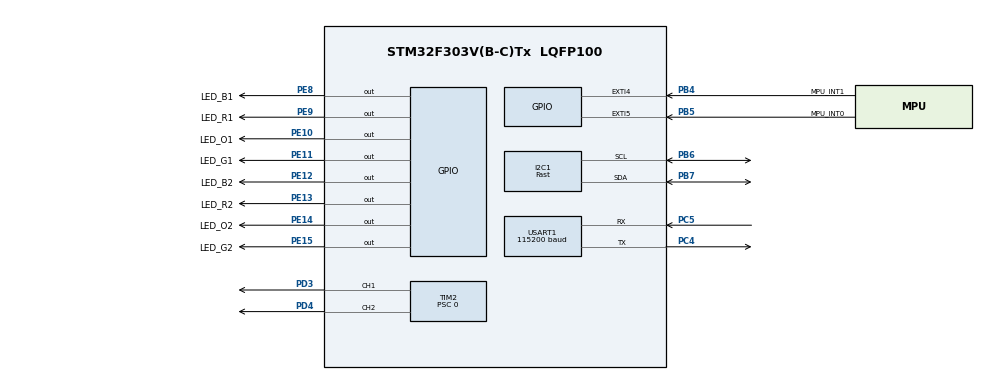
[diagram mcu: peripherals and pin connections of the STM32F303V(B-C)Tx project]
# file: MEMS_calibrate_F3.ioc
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Dma.Request0=USART1_TX
Dma.USART1_TX.0.Direction=DMA_MEMORY_TO_PERIPH
Dma.USART1_TX.0.Instance=DMA1_Channel4
Dma.USART1_TX.0.MemDataAlignment=DMA_MDATAALIGN_BYTE
Dma.USART1_TX.0.MemInc=DMA_MINC_ENABLE
Dma.USART1_TX.0.Mode=DMA_NORMAL
Dma.USART1_TX.0.PeriphDataAlignment=DMA_PDATAALIGN_BYTE
Dma.USART1_TX.0.PeriphInc=DMA_PINC_DISABLE
Dma.USART1_TX.0.Priority=DMA_PRIORITY_LOW
I2C1.I2C_Speed_Mode=I2C_Fast
I2C1.Timing=0x0000020B
Mcu.Family=STM32F3
Mcu.Name=STM32F303V(B-C)Tx
Mcu.Package=LQFP100
NVIC.DMA1_Channel4_IRQn=true\:0\:0\:false\:false\:true\:false\:true
NVIC.EXTI4_IRQn=true\:0\:0\:false\:false\:true\:true\:true
NVIC.EXTI9_5_IRQn=true\:0\:0\:false\:false\:true\:true\:true
NVIC.PriorityGroup=NVIC_PRIORITYGROUP_4
NVIC.USART1_IRQn=true\:0\:0\:false\:false\:true\:true\:true
PA13.Mode=Trace_Asynchronous_SW
PA13.Signal=SYS_JTMS-SWDIO
PA14.Mode=Trace_Asynchronous_SW
PA14.Signal=SYS_JTCK-SWCLK
PB3.Mode=Trace_Asynchronous_SW
PB3.Signal=SYS_JTDO-TRACESWO
PB4.GPIO_Label=MPU_INT1
PB4.GPIO_PuPd=GPIO_NOPULL
PB4.Signal=GPXTI4
PB5.GPIO_Label=MPU_INT0
PB5.GPIO_PuPd=GPIO_NOPULL
PB5.Signal=GPXTI5
PB6.Mode=I2C
PB6.Signal=I2C1_SCL
PB7.Mode=I2C
PB7.Signal=I2C1_SDA
PC4.Mode=Asynchronous
PC4.Signal=USART1_TX
PC5.Mode=Asynchronous
PC5.Signal=USART1_RX
PD3.GPIO_Speed=GPIO_SPEED_FREQ_HIGH
PD3.Signal=S_TIM2_CH1_ETR
PD4.GPIO_Speed=GPIO_SPEED_FREQ_HIGH
PD4.Signal=S_TIM2_CH2
PE10.GPIO_Label=LED_O1
PE10.Signal=GPIO_Output
PE11.GPIO_Label=LED_G1
PE11.Signal=GPIO_Output
PE12.GPIO_Label=LED_B2
PE12.Signal=GPIO_Output
PE13.GPIO_Label=LED_R2
PE13.Signal=GPIO_Output
PE14.GPIO_Label=LED_O2
PE14.Signal=GPIO_Output
PE15.GPIO_Label=LED_G2
PE15.Signal=GPIO_Output
PE8.GPIO_Label=LED_B1
PE8.Signal=GPIO_Output
PE9.GPIO_Label=LED_R1
PE9.Signal=GPIO_Output
PF0-OSC_IN.Mode=HSE-External-Oscillator
PF0-OSC_IN.Signal=RCC_OSC_IN
PF1-OSC_OUT.Mode=HSE-External-Oscillator
PF1-OSC_OUT.Signal=RCC_OSC_OUT
ProjectManager.HeapSize=0x200
ProjectManager.StackSize=0x400
ProjectManager.TargetToolchain=STM32CubeIDE
RCC.AHBFreq_Value=72000000
RCC.APB1CLKDivider=RCC_HCLK_DIV2
RCC.APB1Freq_Value=36000000
RCC.APB1TimFreq_Value=72000000
RCC.APB2Freq_Value=72000000
RCC.APB2TimFreq_Value=72000000
RCC.CortexFreq_Value=72000000
RCC.HCLKFreq_Value=72000000
RCC.HSE_VALUE=8000000
RCC.HSI_VALUE=8000000
RCC.LSE_VALUE=32768
RCC.PLLMUL=RCC_PLL_MUL9
RCC.PLLSourceVirtual=RCC_PLLSOURCE_HSE
RCC.SYSCLKFreq_VALUE=72000000
RCC.SYSCLKSourceVirtual=RCC_SYSCLKSOURCE_PLLCLK
RCC.USBFreq_Value=72000000
SH.S_TIM2_CH1_ETR.0=TIM2_CH1,PWM Generation1 CH1
SH.S_TIM2_CH2.0=TIM2_CH2,PWM Generation2 CH2
TIM2.AutoReloadPreload=TIM_AUTORELOAD_PRELOAD_DISABLE
TIM2.Channel-PWM\ Generation1\ CH1=TIM_CHANNEL_1
TIM2.Channel-PWM\ Generation2\ CH2=TIM_CHANNEL_2
TIM2.Period=10000
TIM2.Prescaler=0
TIM2.Pulse-PWM\ Generation1\ CH1=400
TIM2.Pulse-PWM\ Generation2\ CH2=1000
USART1.BaudRate=115200
USART1.VirtualMode-Asynchronous=VM_ASYNC
VP_TIM2_VS_ClockSourceINT.Mode=Internal
board=custom

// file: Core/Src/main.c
/* USER CODE BEGIN Header */
/**
 ******************************************************************************
 * @file           : main.c
 * @brief          : Main program body
 ******************************************************************************
 * @attention
 *
 * <h2><center>&copy; Copyright (c) 2020 STMicroelectronics.
 * All rights reserved.</center></h2>
 *
 * This software component is licensed by ST under BSD 3-Clause license,
 * the "License"; You may not use this file except in compliance with the
 * License. You may obtain a copy of the License at:
 *                        opensource.org/licenses/BSD-3-Clause
 *
 ******************************************************************************
 */
/* USER CODE END Header */

#include "main.h"
#include "dma.h"
#include "i2c.h"
#include "tim.h"
#include "usart.h"
#include "gpio.h"

/* USER CODE BEGIN Includes */
#include "string.h"

extern UART_HandleTypeDef huart1;
/* USER CODE END Includes */

/* USER CODE BEGIN PTD */
int _write(int file, char *ptr, int len)
    {
//    int i = 0;
//    for (i = 0; i < len; i++)
//	ITM_SendChar(*ptr++);
    HAL_UART_Transmit_IT(&huart1, ptr, len);
    return len;
    }
/* USER CODE END PTD */

void SystemClock_Config(void);

/* USER CODE BEGIN 0 */

//extern MPU_DATA mpu;
void Task_led(void)
    {
//    static char str1[60];

//    SetTimerTask(Task_led, 249);
//    u16 len = sprintf(str1, "%d;%d;%d;%d;%d;%d\r\n", mpu.accX1, mpu.accY1,
//	    mpu.accZ1, mpu.accX2, mpu.accY2, mpu.accZ2);
//    //HAL_UART_Transmit(&huart1, (uint8_t*) str1, len, 0x100);
//    HAL_UART_Transmit_DMA(&huart1, str1, len);
    }

/* USER CODE END 0 */

int main(void)
    {

    /* MCU Configuration--------------------------------------------------------*/

    /* Reset of all peripherals, Initializes the Flash interface and the Systick. */
    HAL_Init();

    /* Configure the system clock */
    SystemClock_Config();

    /* USER CODE BEGIN SysInit */
    InitRTOS();
    /* USER CODE END SysInit */

    /* Initialize all configured peripherals */
    MX_GPIO_Init();
    MX_DMA_Init();
    MX_USART1_UART_Init();
    MX_TIM2_Init();
    MX_I2C1_Init();
    position_init();
    /* USER CODE BEGIN 2 */
    //Accel_Init();
    //Acc_read();
    Task_led();
    HAL_TIM_PWM_Start(&htim2, TIM_CHANNEL_1);
    HAL_TIM_PWM_Start(&htim2, TIM_CHANNEL_2);

    /* USER CODE END 2 */

    /* Infinite loop */
    /* USER CODE BEGIN WHILE */
    while (1)
	{
	TaskManager();
	/* USER CODE END WHILE */

	}
    }

void SystemClock_Config(void)
    {
    LL_FLASH_SetLatency(LL_FLASH_LATENCY_2);

    if (LL_FLASH_GetLatency() != LL_FLASH_LATENCY_2)
	{
	Error_Handler();
	}
    LL_RCC_HSE_Enable();

    /* Wait till HSE is ready */
    while (LL_RCC_HSE_IsReady() != 1)
	{

	}
    LL_RCC_HSI_Enable();

    /* Wait till HSI is ready */
    while (LL_RCC_HSI_IsReady() != 1)
	{

	}
    LL_RCC_HSI_SetCalibTrimming(16);
    LL_RCC_PLL_ConfigDomain_SYS(LL_RCC_PLLSOURCE_HSE_DIV_1, LL_RCC_PLL_MUL_9);
    LL_RCC_PLL_Enable();

    /* Wait till PLL is ready */
    while (LL_RCC_PLL_IsReady() != 1)
	{

	}
    LL_RCC_SetAHBPrescaler(LL_RCC_SYSCLK_DIV_1);
    LL_RCC_SetAPB1Prescaler(LL_RCC_APB1_DIV_2);
    LL_RCC_SetAPB2Prescaler(LL_RCC_APB1_DIV_1);
    LL_RCC_SetSysClkSource(LL_RCC_SYS_CLKSOURCE_PLL);

    /* Wait till System clock is ready */
    while (LL_RCC_GetSysClkSource() != LL_RCC_SYS_CLKSOURCE_STATUS_PLL)
	{

	}
    LL_SetSystemCoreClock(72000000);

    /* Update the time base */
    if (HAL_InitTick(TICK_INT_PRIORITY) != HAL_OK)
	{
	Error_Handler();
	};
    LL_RCC_SetUSARTClockSource(LL_RCC_USART1_CLKSOURCE_PCLK2);
    LL_RCC_SetI2CClockSource(LL_RCC_I2C1_CLKSOURCE_HSI);
    }

void Error_Handler(void)
    {
    }

/************************ (C) COPYRIGHT STMicroelectronics *****END OF FILE****/
